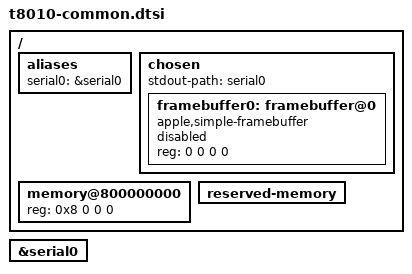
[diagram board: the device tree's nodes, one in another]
// SPDX-License-Identifier: GPL-2.0 OR MIT
/*
 * Apple iPhone 7, iPhone 7 Plus, iPad 6, iPad 7, iPod touch 7
 *
 * This file contains parts common to all Apple A10 devices.
 *
 * target-type: D10, D11, D101, D111, J71b, J72b, J171, J172, N112
 *
 * Copyright (c) 2024, Nick Chan <towinchenmi@gmail.com>
 */

/ {
	aliases {
		serial0 = &serial0;
	};

	chosen {
		#address-cells = <2>;
		#size-cells = <2>;
		ranges;

		stdout-path = "serial0";

		framebuffer0: framebuffer@0 {
			compatible = "apple,simple-framebuffer", "simple-framebuffer";
			reg = <0 0 0 0>; /* To be filled by loader */
			/* Format properties will be added by loader */
			status = "disabled";
		};
	};

	memory@800000000 {
		device_type = "memory";
		reg = <0x8 0 0 0>; /* To be filled by loader */
	};

	reserved-memory {
		#address-cells = <2>;
		#size-cells = <2>;
		ranges;

		/* To be filled by loader */
	};
};

&serial0 {
	status = "okay";
};
